# PAC52XX register map
Vendor: Active-Semi; Series: PAC52XX; File version: 1.0
ARM 32-bit Cortex-M0 Microcontroller based device, with analog and digital peripherals for motor and power control
CPU: CM0 r0p0, little endian, no MPU, no FPU, vendor SysTick, 2 interrupt priority bits
Registers are 32-bit, read-write, reset 0x0 unless marked. A register's access mark holds for its fields unless they carry their own. Offsets are from the block's base; lines under a group give offsets from that group; [hi:lo] are bit positions; {n}, {i} and the like mark numbered series; 'fields as' and 'values as' point back to an identical list; <NAME> marks a mode.

## Memory map
0x40000000 SYSCLK size 0x1000 — System and Clock Control
0x40020000 MEMCTL size 0x1000 — FLASH Memory Controller
0x40030000 WDT size 0x1000 — Watchdog Timer
0x40040000 RTC size 0x1000 — Real-Time Clock
0x40070000 GPIOA size 0x40 — General-Purpose Input-Output Port A
0x40070040 GPIOB size 0x40 — General-Purpose Input-Output Port B
0x40080000 GPIOC size 0x40 — General-Purpose Input-Output Port C
0x40080040 GPIOD size 0x40 — General-Purpose Input-Output Port D
0x40090000 GPIOE size 0x40 — General-Purpose Input-Output Port E
0x400D0000 TIMERA size 0x1000 — Timer A Peripheral
0x400E0000 TIMERB size 0x1000 — Timer B Peripheral
0x400F0000 TIMERC size 0x1000 — Timer C Peripheral
0x40100000 TIMERD size 0x1000 — Timer D Peripheral
0x40150000 ADC size 0x1000 — Analog to Digital Converter
0x401B0000 I2C size 0x1000
0x401D0000 UART size 0x1000
0x40200000 SOCB size 0x1000 — SOC Bus Bridge
0x40210000 SPI size 0x1000

## Interrupts
0 IRQ_MEMCTL (MEMCTL)
1 IRQ_SYSCLK (SYSCLK)
2 IRQ_WDT (WDT)
3 IRQ_GPIOA (GPIOA)
4 IRQ_GPIOB (GPIOB)
5 IRQ_GPIOC (GPIOC)
6 IRQ_GPIOD (GPIOD)
7 IRQ_GPIOE (GPIOE)
8 IRQ_TIMERA (TIMERA)
10 IRQ_TIMERB (TIMERB)
11 IRQ_TIMERC (TIMERC)
12 I_TIMERD (TIMERD) — Timer Interrupt Register
13 IRQ_ADC (ADC)
14 IRQ_SOCB (SOCB)
15 IRQ_SPI (SPI)
16 IRQ_UART (UART)
17 IRQ_I2C (I2C)
19 IRQ_RTC (RTC)

## SYSCLK — System and Clock Control
Base 0x40000000
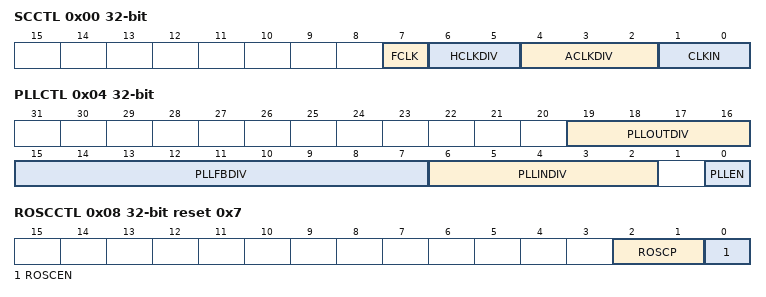
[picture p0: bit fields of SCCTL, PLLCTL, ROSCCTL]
0x00 SCCTL — System Clock Control Register
  [7] FCLK — FCLK input clock select
    0=FRCLK (FCLK = FRCLK); 1=PLLOUT (FCLK = PLLOUT clock)
  [6:5] HCLKDIV — HCLK divider
    0=FCLK /1 (HCLK = FCLK /1); 1=FCLK /2 (HCLK = FCLK /2); 2=FCLK /4 (HCLK = FCLK /4); 3=FCLK /8 (HCLK = FCLK /8)
  [4:2] ACLKDIV — ACLK divider
    0=FCLK /1 (ACLK = FCLK /1); 1=FCLK /2 (ACLK = FCLK /2); 2=FCLK /4 (ACLK = FCLK /4); 3=FCLK /8 (ACLK = FCLK /8); 4=FCLK /16 (ACLK = FCLK /16); 5=FCLK /32 (ACLK = FCLK /32); 6=FCLK /64 (ACLK = FCLK /64); 7=FCLK /128 (ACLK = FCLK /128)
  [1:0] CLKIN — FRCLK input clock select
    0=ROSC (Internal Ring Oscillator); 1=CLKREF (CLKREF input); 2=EXTCLK (External Clock Input); 3=XTAL (Crystal Driver XIN/XOUT Input)
0x04 PLLCTL — PLL Control Register
  [19:16] PLLOUTDIV — PLL Output Divider (divider = /[value+1], 0 reserved)
    1=/1 (PLL output divider: /1)
  [15:7] PLLFBDIV — PLL Feedback Divider (divider = /[value + 2])
    0=/2 (PLL feedback divider: /2)
  [6:2] PLLINDIV — PLL Input Divider (divider = /[value+2])
    0=/2 (PLL input divider: /2)
  [0] PLLEN — PLL enable
    0=Disable PLL; 1=Enable PLL
0x08 ROSCCTL reset 0x7 — Ring Oscillator Control Register
  [2:1] ROSCP — Ring Oscillator Frequency Setting
    0=28.7 MHz (Set Ring Oscillator to 28.7 MHz); 1=15.3 MHz (Set Ring Oscillator to 15.3 MHz); 2=10.7 MHz (Set Ring Oscillator to 10.7 MHz); 3=8.3 MHz (Set Ring Oscillator to 8.3 MHz)
  [0] ROSCEN — Ring Oscillator Enable
    0=Disable Ring Oscillator; 1=Enable Ring Oscillator
0x0C XTALCTL — Crystal Driver Control Register
  [0] XTALEN — Enable XTAL driver
    0=Disable XTAL Driver; 1=Enable XTAL Driver

## Licence text in the file
THIS SOFTWARE IS SUBJECT TO A SOURCE CODE LICENSE AGREEMENT WHICH PROVIDES, AMONG OTHER THINGS: (i) THAT IT CAN BE USED ONLY TO ADAPT THE LICENSEE'S APPLICATION TO PAC PROCESSORS SUPPLIED BY ACTIVE-SEMI INTERNATIONAL; (ii) THAT IT IS PROVIDED "AS IS" WITHOUT WARRANTY; (iii) THAT ACTIVE-SEMICONDUCTOR IS NOT LIABLE FOR ANY INDIRECT DAMAGES OR FOR DIRECT DAMAGES EXCEEDING US$1,500; AND (iv) THAT IT CAN BE DISCLOSED TO AND USED ONLY BY CERTAIN AUTHORIZED PERSONS.

## Notices in the file
Copyright (C) 2015 Active-Semi BVI, Inc. All rights reserved.
